# CC2538SF53 register map
File version: 1
CPU: CM3 r2p1, little endian, no MPU, no FPU, 3 interrupt priority bits
Registers are 32-bit, read-write, reset 0x0 unless marked. A register's access mark holds for its fields unless they carry their own. Offsets are from the block's base; [hi:lo] are bit positions; {n}, {i} and the like mark numbered series.

## USB
Base 0x40089000
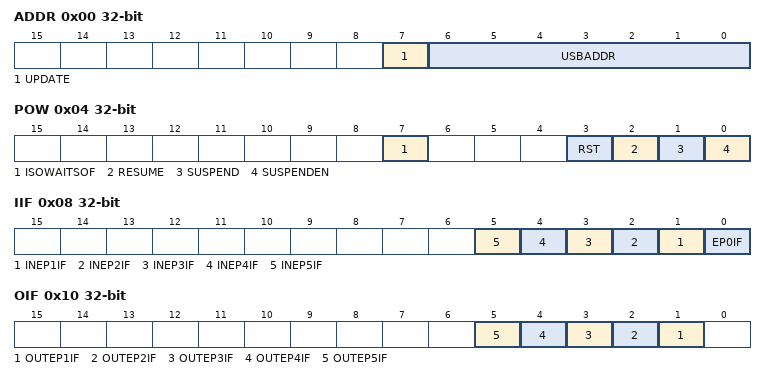
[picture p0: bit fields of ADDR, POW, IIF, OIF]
0x00 ADDR — Function address
  [7] UPDATE ro — This bit is set by hardware when writing to this register, and is cleared by hardware when the new address becomes effective.
  [6:0] USBADDR — Device address. The address shall be updated upon successful completion of the status stage of the SET_ADDRESS request.
0x04 POW — Power management and control register
  [7] ISOWAITSOF — For isochronous mode IN endpoints: When set, the USB controller will wait for an SOF token from the time USB_CSIL.INPKTRDY is set before sending the packet. If an IN token is received before an SOF token, then a zero length data packet will be sent.
  [3] RST ro — Indicates that reset signaling is present on the bus
  [2] RESUME — Drives resume signaling for remote wakeup According to the USB Specification, the resume signal must be held active for at least 1 ms and no more than 15 ms. It is recommended to keep this bit set for approximately 10 ms.
  [1] SUSPEND ro — Indicates entry into suspend mode Suspend mode must be enabled by setting USB_POW.SUSPENDEN Software clears this bit by reading the USB_CIF register or by asserting USB_POW.RESUME
  [0] SUSPENDEN — Enables detection of and entry into suspend mode.
0x08 IIF ro — Interrupt flags for endpoint 0 and IN endpoints 1-5
  [n] INEP{n}IF (n=1..5) — Interrupt flag for IN endpoint {n} Cleared by hardware when read
  [0] EP0IF — Interrupt flag for endpoint 0 Cleared by hardware when read
0x10 OIF ro — Interrupt flags for OUT endpoints 1-5
  [n] OUTEP{n}IF (n=1..5) — Interrupt flag for OUT endpoint {n} Cleared by hardware when read
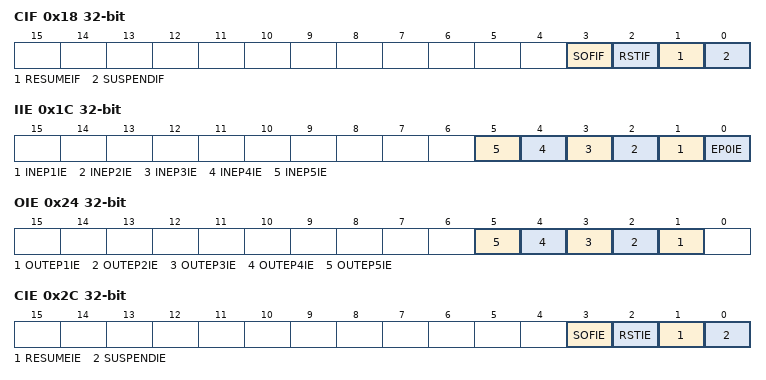
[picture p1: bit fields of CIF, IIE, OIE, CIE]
0x18 CIF ro — Common USB interrupt flags
  [3] SOFIF — Start-of-frame interrupt flag Cleared by hardware when read
  [2] RSTIF — Reset interrupt flag Cleared by hardware when read
  [1] RESUMEIF — Resume interrupt flag Cleared by hardware when read
  [0] SUSPENDIF — Suspend interrupt flag Cleared by hardware when read
0x1C IIE — Interrupt enable mask for IN endpoints 1-5 and endpoint 0
  [n] INEP{n}IE (n=1..5) — Interrupt enable for IN endpoint {n} 0: Interrupt disabled 1: Interrupt enabled
  [0] EP0IE — Interrupt enable for endpoint 0 0: Interrupt disabled 1: Interrupt enabled
0x24 OIE — Interrupt enable mask for OUT endpoints 1-5
  [n] OUTEP{n}IE (n=1..5) — Interrupt enable for OUT endpoint {n} 0: Interrupt disabled 1: Interrupt enabled
0x2C CIE — Common USB interrupt enable mask
  [3] SOFIE — Start-of-frame interrupt enable 0: Interrupt disabled 1: Interrupt enabled
  [2] RSTIE — Reset interrupt enable 0: Interrupt disabled 1: Interrupt enabled
  [1] RESUMEIE — Resume interrupt enable 0: Interrupt disabled 1: Interrupt enabled
  [0] SUSPENDIE — Suspend interrupt enable 0: Interrupt disabled 1: Interrupt enabled
0x30 FRML ro — Frame number (low byte)
  [7:0] FRAMEL — Bits 7:0 of the 11-bit frame number The frame number is only updated upon successful reception of SOF tokens
0x34 FRMH ro — Frame number (high byte)
  [2:0] FRAMEH — Bits 10:8 of the 11-bit frame number The frame number is only updated upon successful reception of SOF tokens
0x38 INDEX — Index register for selecting the endpoint status and control registers
  [3:0] USBINDEX — Index of the currently selected endpoint The index is set to 0 to enable access to endpoint 0 control and status registers The index is set to 1, 2, 3, 4 or 5 to enable access to IN/OUT endpoint 1, 2, 3, 4 or 5 control and status registers, respectively
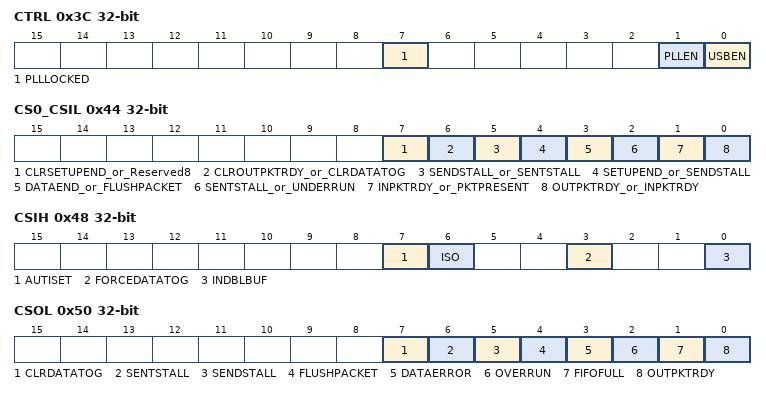
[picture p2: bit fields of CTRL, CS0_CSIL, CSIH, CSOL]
0x3C CTRL — USB peripheral control register
  [7] PLLLOCKED ro — PLL lock status. The PLL is locked when USB_CTRL.PLLLOCKED is 1.
  [1] PLLEN — 48 MHz USB PLL enable When this bit is set, the 48 MHz PLL is started. Software must avoid access to other USB registers before the PLL has locked; that is, USB_CTRL.PLLLOCKED is 1. This bit can be set only when USB_CTRL.USBEN is 1. The PLL must be disabled before entering PM1 when suspended, and must be re-enabled when resuming operation.
  [0] USBEN — USB enable The USB controller is reset when this bit is cleared
0x40 MAXI — Indexed register: For USB_INDEX = 1-5: Maximum packet size for IN endpoint {1-5}
  [7:0] USBMAXI — Maximum packet size, in units of 8 bytes, for the selected IN endpoint The value of this register should match the wMaxPacketSize field in the standard endpoint descriptor for the endpoint. The value must not exceed the available memory.
0x44 CS0_CSIL — Indexed register: For USB_INDEX = 0: Endpoint 0 control and status For USB_INDEX = 1-5: IN endpoint {1-5} control and status (low byte)
  [7] CLRSETUPEND_or_Reserved8 — USB_CS0.CLRSETUPEND [RW]: Software sets this bit to clear the USB_CS0.SETUPEND bit. It is cleared automatically. USB_CSIL.Reserved [RO]: Reserved
  [6] CLROUTPKTRDY_or_CLRDATATOG — USB_CS0.CLROUTPKTRDY [RW]: Software sets this bit to clear the USB_CS0.OUTPKTRDY bit. It is cleared automatically. USB_CSIL.CLRDATATOG [RW]: Software sets this bit to reset the IN endpoint data toggle to 0.
  [5] SENDSTALL_or_SENTSTALL — USB_CS0.SENDSTALL [RW]: Software sets this bit to terminate the current transaction with a STALL handshake. The bit is cleared automatically when the STALL handshake has been transmitted. USB_CSIL.SENTSTALL [RW]: For bulk/interrupt mode IN endpoints: This bit is set when a STALL handshake is transmitted. The FIFO is flushed and the USB_CSIL.INPKTRDY bit cleared. Software should clear this bit.
  [4] SETUPEND_or_SENDSTALL ro — USB_CS0.SETUPEND [RO]: This bit is set when a control transaction ends before the USB_CS0.DATAEND bit has been set. An interrupt is generated and the FIFO flushed at this time. Software clears this bit by setting USB_CS0.CLRSETUPEND. CSIL.SENDSTALL [RW]: For bulk/interrupt mode IN endpoints: Software sets this bit to issue a STALL handshake. Software clears this bit to terminate the stall condition.
  [3] DATAEND_or_FLUSHPACKET — USB_CS0.DATAEND [RW]: This bit is used to signal the end of the data stage, and must be set: 1. When the last data packet is loaded and USB_CS0.INPKTRDY is set. 2. When the last data packet is unloaded and USB_CS0.CLROUTPKTRDY is set. 3. When USB_CS0.INPKTRDY is set to send a zero-length packet. The USB controller clears this bit automatically. USB_CSIL.FLUSHPACKET [RW]: Software sets this bit to flush the next packet to be transmitted from the IN endpoint FIFO. The FIFO pointer is reset and the USB_CSIL.INPKTRDY bit is cleared. Note: If the FIFO contains two packets, USB_CSIL.FLUSHPACKET will need to be set twice to completely clear the FIFO.
  [2] SENTSTALL_or_UNDERRUN — USB_CS0.SENTSTALL [RW]: This bit is set when a STALL handshake is sent. An interrupt is generated is generated when this bit is set. Software must clear this bit. USB_CSIL.UNDERRUN [RW]: In isochronous mode, this bit is set when a zero length data packet is sent after receiving an IN token with USB_CSIL.INPKTRDY not set. In bulk/interrupt mode, this bit is set when a NAK is returned in response to an IN token. Software should clear this bit.
  [1] INPKTRDY_or_PKTPRESENT — USB_CS0. INPKTRDY [RW]: Software sets this bit after loading a data packet into the endpoint 0 FIFO. It is cleared automatically when the data packet has been transmitted. An interrupt is generated when the bit is cleared. USB_CSIL.PKTPRESENT [RO]: This bit is set when there is at least one packet in the IN endpoint FIFO.
  [0] OUTPKTRDY_or_INPKTRDY ro — USB_CS0.OUTPKTRDY [RO]: Endpoint 0 data packet received An interrupt request (EP0) is generated if the interrupt is enabled. Software must read the endpoint 0 FIFO empty, and clear this bit by setting USB_CS0.CLROUTPKTRDY USB_CSIL.INPKTRDY [RW]: IN endpoint {1-5} packet transfer pending Software sets this bit after loading a data packet into the FIFO. It is cleared automatically when a data packet has been transmitted. An interrupt is generated (if enabled) when the bit is cleared. When using double-buffering, the bit is cleared immediately if the other FIFO is empty.
0x48 CSIH — Indexed register: For USB_INDEX = 1-5: IN endpoint {1-5} control and status (high byte)
  [7] AUTISET — If set by software, the USB_CSIL.INPKTRDY bit is automatically set when a data packet of maximum size (specified by USBMAXI) is loaded into the IN endpoint FIFO. If a packet of less than the maximum packet size is loaded, then USB_CSIL.INPKTRDY will have to be set manually.
  [6] ISO — Selects IN endpoint type: 0: Bulk/interrupt 1: Isochronous
  [3] FORCEDATATOG — Software sets this bit to force the IN endpoint's data toggle to switch after each data packet is sent regardless of whether an ACK was received. This can be used by interrupt IN endpoints which are used to communicate rate feedback for isochronous endpoints.
  [0] INDBLBUF — IN endpoint FIFO double-buffering enable: 0: Double buffering disabled 1: Double buffering enabled
0x4C MAXO — Indexed register: For USB_INDEX = 1-5: Maximum packet size for OUT endpoint {1-5}
  [7:0] USBMAXO — Maximum packet size, in units of 8 bytes, for the selected OUT endpoint The value of this register should match the wMaxPacketSize field in the standard endpoint descriptor for the endpoint. The value must not exceed the available memory.
0x50 CSOL — Indexed register: For USB_INDEX = 1-5: OUT endpoint {1-5} control and status (low byte)
  [7] CLRDATATOG — Software sets this bit to reset the endpoint data toggle to 0.
  [6] SENTSTALL — This bit is set when a STALL handshake is transmitted. An interrupt is generated when this bit is set. Software should clear this bit.
  [5] SENDSTALL — For bulk/interrupt mode OUT endpoints: Software sets this bit to issue a STALL handshake. Software clears this bit to terminate the stall condition.
  [4] FLUSHPACKET — Software sets this bit to flush the next packet to be read from the endpoint OUT FIFO. Note: If the FIFO contains two packets, USB_CSOL.FLUSHPACKET will need to be set twice to completely clear the FIFO.
  [3] DATAERROR ro — For isochronous mode OUT endpoints: This bit is set when USB_CSOL.OUTPKTRDY is set if the data packet has a CRC or bit-stuff error. It is cleared automatically when USB_CSOL.OUTPKTRDY is cleared.
  [2] OVERRUN — For isochronous mode OUT endpoints: This bit is set when an OUT packet cannot be loaded into the OUT endpoint FIFO. Firmware should clear this bit.
  [1] FIFOFULL ro — This bit is set when no more packets can be loaded into the OUT endpoint FIFO.
  [0] OUTPKTRDY — This bit is set when a data packet has been received. Software should clear this bit when the packet has been unloaded from the OUT endpoint FIFO. An interrupt is generated when the bit is set.
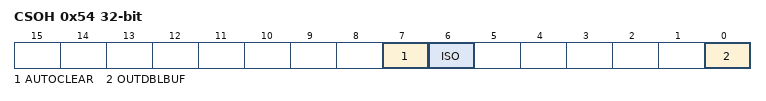
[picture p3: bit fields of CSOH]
0x54 CSOH — Indexed register: For USB_INDEX = 1-5: OUT endpoint {1-5} control and status (high byte)
  [7] AUTOCLEAR — If software sets this bit, the USB_CSOL.OUTPKTRDY bit will be automatically cleared when a packet of maximum size (specified by USB_MAXO) has been unloaded from the OUT FIFO. When packets of less than the maximum packet size are unloaded, USB_CSOL.OUTPKTRDY will have to be cleared manually.
  [6] ISO — Selects OUT endpoint type: 0: Bulk/interrupt 1: Isochronous
  [0] OUTDBLBUF — OUT endpoint FIFO double-buffering enable: 0: Double buffering disabled 1: Double buffering enabled
0x58 CNT0_CNTL ro — Indexed register: For USB_INDEX = 0: Number of received bytes in the endpoint 0 FIFO For USB_INDEX = 1-5: Number of received bytes in the OUT endpoint {1-5} FIFO (low byte)
  [7:0] FIFOCNT_or_FIFOCNTL — USB_CS0.FIFOCNT (USBINDEX = 0) [RO]: Number of bytes received in the packet in the endpoint 0 FIFO Valid only when USB_CS0.OUTPKTRDY is set USB_CSIL.FIFOCNTL (USBINDEX = 1 to 5) [RW]: Bits 7:0 of the of the number of bytes received in the packet in the OUT endpoint {1-5} FIFO Valid only when USB_CSOL.OUTPKTRDY is set
0x5C CNTH ro — Indexed register: For USB_INDEX = 1-5: Number of received in the OUT endpoint {1-5} FIFO (high byte)
  [2:0] FIFOCNTH — Bits 10:8 of the of the number of bytes received in the packet in the OUT endpoint {1-5} FIFO Valid only when USB_CSOL.OUTPKTRDY is set
0x80 F0 — Endpoint 0 FIFO
  [7:0] USBF0 — Endpoint 0 FIFO Reading this register unloads one byte from the endpoint 0 FIFO. Writing to this register loads one byte into the endpoint 0 FIFO. The FIFO memory for EP0 is used for incoming and outgoing data packets.
{0x80+8i} F{i} (i=1..5) — IN/OUT endpoint {i} FIFO
  [7:0] USBF{i} — Endpoint {i} FIFO register Reading this register unloads one byte from the EP{i} OUT FIFO. Writing to this register loads one byte into the EP{i} IN FIFO.
